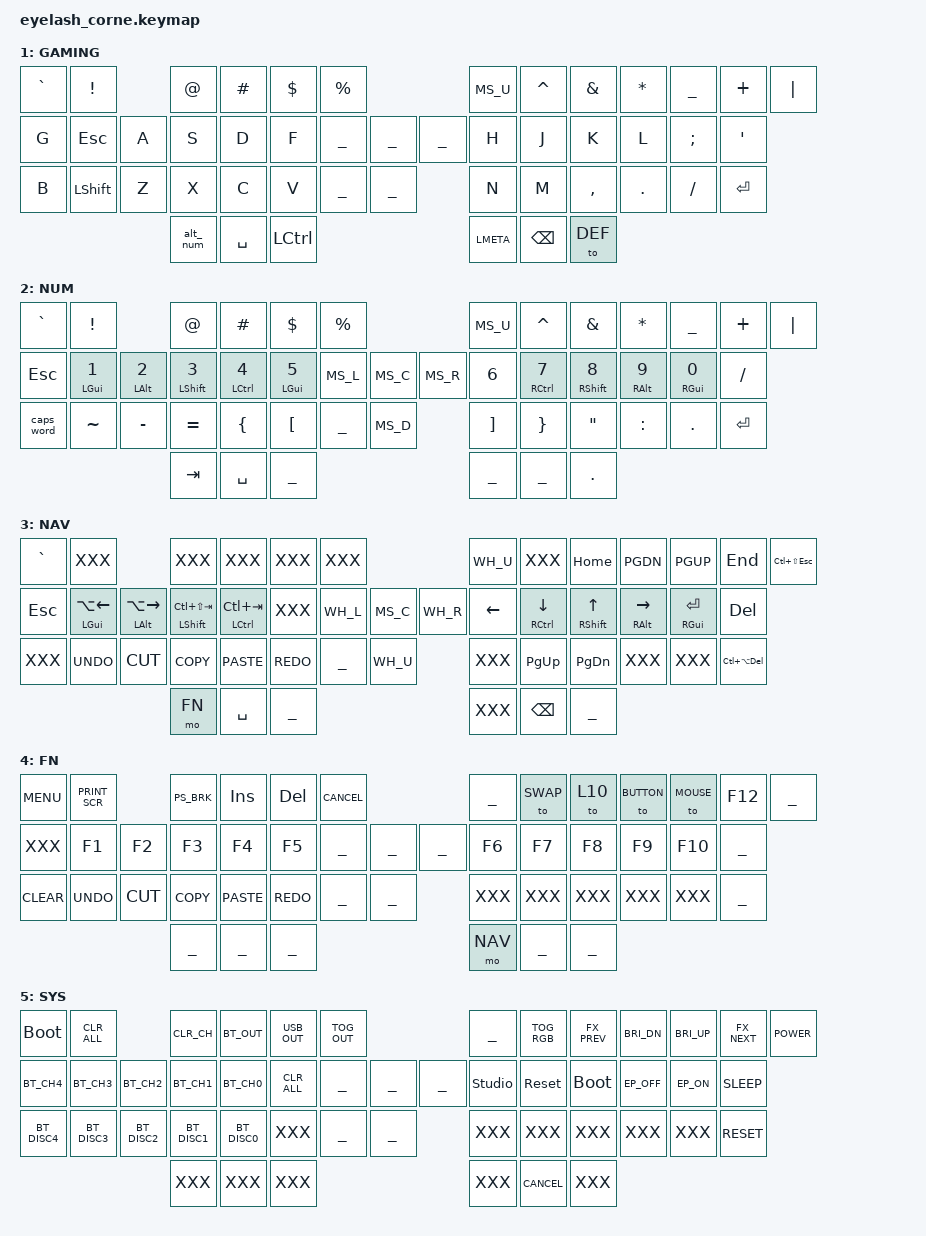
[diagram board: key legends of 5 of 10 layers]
#define CONFIG_WIRELESS

#include "eyelash_matrix.h"
#include "base.keymap"
#include <dt-bindings/zmk/keys.h>

/*
  layout:  the block in the middle is
    - the encoder push button (lower left)
    - the mini joystick & in the center, it's push button

  bindings = <
    XXX XXX XXX XXX XXX XXX     ___      XXX XXX XXX XXX XXX XXX
    XXX XXX XXX XXX XXX XXX ___ ___ ___  XXX XXX XXX XXX XXX XXX
    XXX XXX XXX XXX XXX XXX ___ ___      XXX XXX XXX XXX XXX XXX
                XXX XXX XXX              XXX XXX XXX
  >;
*/

/ {

  /* encoder behaviours */

  rgb_encoder: rgb_encoder {
    compatible = "zmk,behavior-sensor-rotate";
    #sensor-binding-cells = <0>;
    bindings = <&rgb_ug RGB_BRI>, <&rgb_ug RGB_BRD>;
  };

        /* rgb_encoder: rgb_encoder { */
        /*     compatible = "zmk,behavior-sensor-rotate"; */
        /*     label = "RGB_ENCODER"; */
        /*     #sensor-binding-cells = <0>; */
        /*     bindings = <&rgb_ug RGB_BRI>, <&rgb_ug RGB_BRD>; */
        /**/
        /*     tap-ms = <5>; */
        /* }; */

        scroll_encoder: scroll_encoder {
            compatible = "zmk,behavior-sensor-rotate";
            label = "scroll_encoder";
            #sensor-binding-cells = <0>;
            bindings = <&msc SCRL_UP>, <&msc SCRL_DOWN>;

            tap-ms = <5>;
        };

  /* layout */

  keymap {
    compatible = "zmk,keymap";

    /*************************
     * DEF: QWERTY default keymap
     *************************/

    default_layer {
      display-name = "BASE";

      bindings = <
      GRV_HYP &as LS(F10) Q    &kp W     &as END E          &as LC(LS(Z)) R &kp T       _UP       &kp Y   &kp U  &kp I    &kp O     &kp P      &as RC(RS(ESC)) MINUS
      ESC_MEH &kp A  _HOME_ROW_MODS_LEFT_         _L_ _RT _R_   &as HOME H   _HOME_ROW_MODS_RIGHT_                &kp SQT
      &lt 3 LA(TAB) &kp Z  &as DEL X  &kp C  &as LC(LA(LS(V))) V  &as N0 B   _PP _DN       &kp N   &as PG_DN M       &as PG_UP COMMA  &kp DOT &kp SLASH  &as RC(RA(DEL)) EQUAL
                   &fn_esc__cmd  NUM_SPC  CTL_TAB               NAV_KEY BS_SFT NUM_WORD
       >;

      sensor-bindings = <&scroll_encoder>;
    };

    /*************************
     * GAM: gaming layer
     *************************/

    gaming_layer {
      display-name = "GAMING";

      // QUERTY, but adjusted for columnar stagger so WASD is in the ESDF position

      bindings = <
      &kp GRAVE  &kp EXCL  &kp AT    &kp HASH  &kp DOLLAR &kp PERCENT          MS_U      &kp CARET &kp AMPS &kp STAR &kp UNDER &kp PLUS &kp PIPE
      &kp G  &kp ESC   &kp A  &kp S     &kp D    &kp F     ___ ___ ___     &kp H      &kp J     &kp K      &kp L    &kp SEMI  &kp SQT
      &kp B  &kp LSHFT &kp Z  &kp X     &kp C    &kp V     ___ ___         &kp N      &kp M     &kp COMMA  &kp DOT  &kp SLASH &kp RET
                              &alt__num &kp SPC  &kp LCTRL                 &kp LMETA  &kp BSPC  &to DEF
      >;

      sensor-bindings = <&inc_dec_kp C_VOLUME_UP C_VOLUME_DOWN>;
    };

    /*************************
     * NUM: numbers & symbols
     *************************/

    num_layer {
      display-name = "NUM";

      bindings = <
      &kp GRAVE  &kp EXCL  &kp AT    &kp HASH  &kp DOLLAR &kp PERCENT          MS_U      &kp CARET &kp AMPS &kp STAR &kp UNDER &kp PLUS &kp PIPE
      &kp ESC    &hml LGUI N1  &hml LALT N2  &hml LSHFT N3  &hml LCTRL N4  &hml LGUI N5        MS_L MS_C MS_R   &kp N6     &hmr RCTRL N7         &hmr RSHFT N8    &hmr RALT N9   &hmr RGUI N0   &kp SLASH
      &caps_word &kp TILDE &kp MINUS &kp EQUAL &kp LBRC   &kp LBKT      ___    MS_D      &kp RBKT  &kp RBRC &kp DQT  &kp COLON &kp DOT  &kp ENTER
                                     &kp TAB   &kp SPC    ___                            ___       ___      &kp DOT
      >;

      sensor-bindings = <&inc_dec_kp PG_DN PG_UP>;
    };

    /*************************
     * NAV: Navigation
     *************************/

    nav_layer {
      display-name = "NAV";

      bindings = <
      &kp GRAVE XXX        XXX       XXX        XXX         XXX          WH_U        XXX   &kp HOME &kp PGDN &kp PGUP &kp END   &kp LC(LS(ESC))
      &kp ESC   &hml LGUI LA(LEFT)  &hml LALT LA(RIGHT)  &hml LEFT_SHIFT LC(LS(TAB))  &hml LCTRL LC(TAB)  XXX     WH_L MS_C WH_R    &kp LEFT &hmr RCTRL DOWN &hmr RSHFT UP   &hmr RALT RIGHT &hmr RGUI RET &kp DEL
      XXX       _UNDO      _CUT      _COPY      _PASTE      _REDO   ___  WH_U        XXX      &kp PG_UP      &kp PG_DN    XXX   XXX   &kp LC(LA(DEL))
      &mo FN     &kp SPACE   ___                      XXX   &kp BSPC ___
      >;

      sensor-bindings = <&inc_dec_kp PG_DN PG_UP>;
    };

    /*************************
     * FUN: Function keys & extended keys
     *************************/

    function_layer {
      display-name = "FN";

      bindings = <
      &kp K_MENU  PRINT_SCR  PS_BRK  &kp INS  &kp DEL  &kp K_CANCEL     ___       &to SWAP       &to L10     &to BUTTON     &to MOUSE  &kp F12  ___
      XXX         &kp F1     &kp F2  &kp F3   &kp F4   &kp F5       ___ ___ ___   &kp F6    &kp F7  &kp F8  &kp F9   &kp F10  ___
      &kp CLEAR   _UNDO      _CUT    _COPY    _PASTE   _REDO        ___ ___       XXX       XXX     XXX     XXX      XXX      ___
                                     ___      ___      ___                        &mo NAV   ___     ___
      >;

      sensor-bindings = <&rgb_encoder>;
    };

    /*************************
     * SYS: System - bluetooth, power, etc
     *************************/

    sys_layer {
      display-name = "SYS";
      bindings = <
      &bootloader  CLR_ALL     CLR_CH   BT_OUT    USB_OUT    TOG_OUT        ___       TOG_RGB         FX_PREV       BRI_DN       BRI_UP   FX_NEXT &kp C_POWER
      BT_CH4      BT_CH3   BT_CH2    BT_CH1     BT_CH0  CLR_ALL     ___ ___ ___   &studio_unlock  &sys_reset    &bootloader  _EP_OFF  _EP_ON  &kp K_SLEEP
      BT_DISC4  BT_DISC3    BT_DISC2 BT_DISC1  BT_DISC0   XXX   ___ ___       XXX             XXX           XXX          XXX      XXX     &kp C_RESET
                                XXX       XXX        XXX                      XXX             &kp K_CANCEL  XXX
      >;

      /* XXX  BT_CLR_ALL  BT_CLR   BT_OUT    USB_OUT    TOG_OUT        ___       TOG_RGB         FX_PREV       BRI_DN       BRI_UP   FX_NEXT &kp C_POWER */
      /* XXX  BT_CH0      BT_CH1   BT_CH2    BT_CH3     BT_CH4     ___ ___ ___   &studio_unlock  &sys_reset    &bootloader  _EP_OFF  _EP_ON  &kp K_SLEEP */
      /* XXX  BT_DISC0    BT_DISC1 BT_DISC2  BT_DISC3   BT_DISC4   ___ ___       XXX             XXX           XXX          XXX      XXX     &kp C_RESET */

      sensor-bindings = <&rgb_encoder>;
    };

    /*************************
     * SWAP
     *************************/

    swap_layer {
      display-name = "SWAP";
      bindings = <
      &bootloader  ___      &kp LA(F4)  ___      &bt BT_PRV  &bt BT_NXT      &kp LC(W)    &kp LG(LC(LA(N1)))  &kp LG(LC(LA(N2)))  &kp LG(LC(LA(N3)))  &kp LG(LC(LA(N4)))  &kp LG(LC(LA(N5)))  &bootloader
      &kp ESC      &kp LC(LG(N1))  &kp LC(LG(N2))  &kp LC(LG(N3))  &kp LC(LG(N4))  &kp LC(LG(N5))      ___    ___    ___    &kp LC(LG(N6))      &kp LC(LG(N7))      &kp LC(LG(N8))      &kp LC(LG(N9))      &kp LC(LG(N0))      &kp ESC
      &bt BT_CLR   &kp LC(LG(N0))  &kp LC(LG(N9))  &kp LC(LG(N8))  &bt BT_PRV  &bt BT_NXT  ___    &kp LC(LS(TAB))  &bt BT_SEL 0        &bt BT_SEL 1        &bt BT_SEL 2        &bt BT_SEL 3        &bt BT_SEL 4        &bt BT_CLR
                               &kp N0  &kp LS(LA(LC(LG(F9))))  &lt 10 LA(F4)    &mo 0        &kp LC(TAB)      &as RG(TAB) C_PREV  &as C_MUTE LA(F4)   &as RS(RA(RC(RG(F11)))) C_NEXT
      >;
      sensor-bindings = <&inc_dec_kp C_VOLUME_UP C_VOLUME_DOWN>;
    };

    /*************************
     * L10
     *************************/

    L10 {
      display-name = "L10";
      bindings = <
      &bootloader  ___                 &kp LA(F15)          ___              &kp LC(LA(LS(F20)))  &kp F21                  &kp LA(F15)  ___   &kp LG(LEFT)  &kp LG(DOWN)      &kp LG(UP) &kp LG(RIGHT)  &kp RC(RS(ESC))
      &kp ESC      &hml LWIN LA(F13)  &hml LALT LA(F14)    &hml LSHFT LC(F13)  &hml LCTRL LC(F22)   &hml LWIN LG(TAB)  ___  ___ &kp LA(F14)  &kp F13  &hmr RCTRL F14   &hmr RSHFT F15       &hmr RALT F22    &to 0            ___
      &bt BT_CLR   &bt BT_NXT             &kp LC(LS(LA(F17)))  ___              &kp LC(LS(V))        &as LS(X) B       ___       &kp LA(F13)  ___   &kp RS(RA(F17))  &kp RS(RA(F18))      &kp F19          &kp F20          &kp RC(RA(DEL))
                                          &to 0                &kp F21             &kp F21              &key_repeat              &kp LA(F22)  &to 0    &lt 6 RA(F4)    ___
      >;
    };

    /*************************
     * Button
     *************************/

    button_layer {
      display-name = "BUTTON";
      bindings = <
      &kp CAPS  &kp LS(LG(LC(LA(Q))))  &kp LA(F4)  &kp LG(LC(LA(E)))         &kp LC(F24)              &as N3 LS(LA(LC(LG(T))))          ___  ___             ___              ___             ___      &kp LG(LC(LA(P)))    &kp RC(RS(ESC))
      ___    &kp LG(LC(LA(T)))      &kp F24     &kp LS(F24)               &kp LG(LC(LA(F)))        &kp LG(LC(LA(G)))      ___    ___           ___  &kp LG(LC(LA(H)))  &kp LG(LEFT)  &kp LG(DOWN)       &kp LG(UP)  &kp LG(RIGHT)  ___
      ___    &kp LG(X)       ___      &kp LG(LC(LA(C)))         &kp LS(LC(V))            &as N3 LS(LA(LC(LG(B))))    ___      ___  ___             ___              ___             ___      ___               &kp RC(RA(DEL))
                                 ___      &as LC(LA(LS(M))) C_PREV  &as C_MUTE C_PP  &as LS(LG(LA(LC(F11)))) C_NEXT    ___  &kp F24            &kp RS(F24)         &kp LG(LC(LA(H)))
      >;
      sensor-bindings = <&inc_dec_kp LC(LS(TAB)) LC(LS(TAB))>;
    };

    /*************************
     * Mouse
     *************************/

    mouse {
      display-name = "MOUSE";
      bindings = <
      &bootloader  &kp LS(F10)     &mmv MOVE_UP    &kp RET          &mkp LCLK            &msc SCRL_UP      &msc SCRL_UP         &msc SCRL_LEFT        &msc SCRL_DOWN       &msc SCRL_UP         &msc SCRL_RIGHT     &msc SCRL_LEFT  ___
      &kp ESC      &mmv MOVE_LEFT  &mmv MOVE_DOWN  &mmv MOVE_RIGHT  &hmr LCTRL RCLK  &msc SCRL_DOWN &msc SCRL_LEFT   &to 0    &msc SCRL_RIGHT            &kp HOME              &hmr RCTRL RCLK  &hmr LSHFT LCLK  &hmr RALT MCLK  &to 0           &to 0
      &bt BT_CLR   &msc SCRL_LEFT  &msc SCRL_DOWN  &msc SCRL_RIGHT  &mkp RCLK    &as N5 B     ___    &msc SCRL_DOWN   &as LC(END) LC(HOME)  &kp PG_DN            &kp PG_UP            ___              ___          &to 0
                   &to 0           &mkp MCLK        &mkp LCLK            &mkp RCLK         ___   &mkp LCLK             &mkp RCLK            &mkp MCLK
      >;
      sensor-bindings = <&inc_dec_kp UP_ARROW DOWN_ARROW>;
    };

    // activate SYS when FN + NAV held
    //
    conditional_layers {
      compatible = "zmk,conditional-layers";
      tri_layer {
        if-layers = <NAV FN>;
        then-layer = <SYS>;
      };
    };

  };
};
